# ESP32-S31 register map
Vendor: ESPRESSIF SYSTEMS (SHANGHAI) CO., LTD.; Series: ESP32 S-Series; File version: 1
CPU: RV32IMAFC r0p0, little endian, no MPU, FPU, 0 interrupt priority bits
Address unit: 32 bits
Registers are 32-bit, read-write, reset 0x0 unless marked. A register's access mark holds for its fields unless they carry their own. Offsets are from the block's base; [hi:lo] are bit positions; {n}, {i} and the like mark numbered series.

## LP_SYS — LP System Registers
Base 0x20700000
0x00 VER_DATE reset 0x20250923
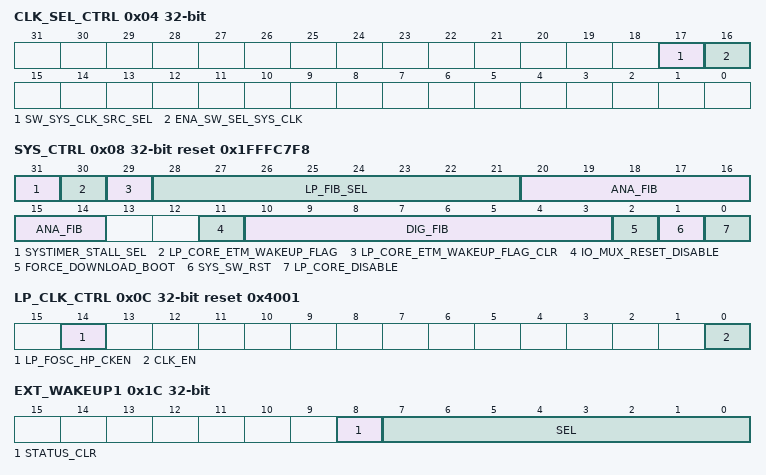
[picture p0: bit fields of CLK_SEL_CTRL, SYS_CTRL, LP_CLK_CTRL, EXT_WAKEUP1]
0x04 CLK_SEL_CTRL
  [17] SW_SYS_CLK_SRC_SEL, [16] ENA_SW_SEL_SYS_CLK
0x08 SYS_CTRL access per field reset 0x1FFFC7F8
  [31] SYSTIMER_STALL_SEL rw, [30] LP_CORE_ETM_WAKEUP_FLAG rw, [29] LP_CORE_ETM_WAKEUP_FLAG_CLR wo, [28:21] LP_FIB_SEL rw, [20:14] ANA_FIB ro, [11] IO_MUX_RESET_DISABLE rw, [10:3] DIG_FIB rw, [2] FORCE_DOWNLOAD_BOOT rw, [1] SYS_SW_RST wo, [0] LP_CORE_DISABLE rw
0x0C LP_CLK_CTRL reset 0x4001
  [14] LP_FOSC_HP_CKEN, [0] CLK_EN
0x18 LP_CORE_BOOT_ADDR reset 0x2E000000
  [31:0] LP_CPU_BOOT_ADDR
0x1C EXT_WAKEUP1 access per field
  [8] STATUS_CLR wo, [7:0] SEL rw
0x20 EXT_WAKEUP1_STATUS ro
  [7:0] EXT_WAKEUP1_STATUS
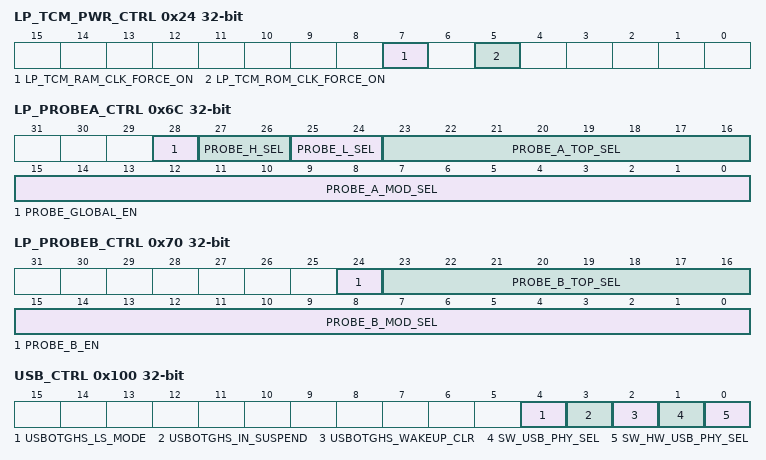
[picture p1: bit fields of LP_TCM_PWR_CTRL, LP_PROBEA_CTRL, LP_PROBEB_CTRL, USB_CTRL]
0x24 LP_TCM_PWR_CTRL
  [7] LP_TCM_RAM_CLK_FORCE_ON, [5] LP_TCM_ROM_CLK_FORCE_ON
0x28 BOOT_ADDR_HP_LP_REG
  [31:0] BOOT_ADDR_HP_LP
{0x2C+4i} LP_STORE{i} (i=0..15)
  [31:0] LP_SCRATCH0
0x6C LP_PROBEA_CTRL
  [28] PROBE_GLOBAL_EN, [27:26] PROBE_H_SEL, [25:24] PROBE_L_SEL, [23:16] PROBE_A_TOP_SEL, [15:0] PROBE_A_MOD_SEL
0x70 LP_PROBEB_CTRL
  [24] PROBE_B_EN, [23:16] PROBE_B_TOP_SEL, [15:0] PROBE_B_MOD_SEL
0x74 LP_PROBE_OUT ro
  [31:0] PROBE_TOP_OUT
0x9C F2S_APB_BRG_CNTL
  [0] F2S_APB_POSTW_EN
0x100 USB_CTRL access per field
  [4] USBOTGHS_LS_MODE rw, [3] USBOTGHS_IN_SUSPEND rw, [2] USBOTGHS_WAKEUP_CLR wo, [1] SW_USB_PHY_SEL rw, [0] SW_HW_USB_PHY_SEL rw
0x10C ANA_XPD_PAD_GROUP reset 0xFF
  [7:0] ANA_REG_XPD_PAD_GROUP
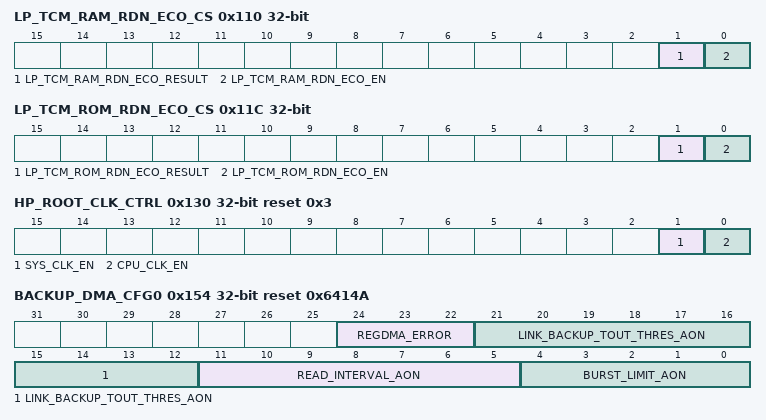
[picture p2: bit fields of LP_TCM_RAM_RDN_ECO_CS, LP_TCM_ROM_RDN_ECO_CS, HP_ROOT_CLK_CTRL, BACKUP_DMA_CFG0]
0x110 LP_TCM_RAM_RDN_ECO_CS access per field
  [1] LP_TCM_RAM_RDN_ECO_RESULT ro, [0] LP_TCM_RAM_RDN_ECO_EN rw
0x114 LP_TCM_RAM_RDN_ECO_LOW
0x118 LP_TCM_RAM_RDN_ECO_HIGH reset 0xFFFFFFFF
0x11C LP_TCM_ROM_RDN_ECO_CS access per field
  [1] LP_TCM_ROM_RDN_ECO_RESULT ro, [0] LP_TCM_ROM_RDN_ECO_EN rw
0x120 LP_TCM_ROM_RDN_ECO_LOW
0x124 LP_TCM_ROM_RDN_ECO_HIGH reset 0xFFFFFFFF
0x130 HP_ROOT_CLK_CTRL reset 0x3
  [1] SYS_CLK_EN, [0] CPU_CLK_EN
0x138 LP_PMU_RDN_ECO_LOW
  [31:0] PMU_RDN_ECO_LOW
0x13C LP_PMU_RDN_ECO_HIGH reset 0xFFFFFFFF
  [31:0] PMU_RDN_ECO_HIGH
0x154 BACKUP_DMA_CFG0 access per field reset 0x6414A
  [24:22] REGDMA_ERROR ro, [21:12] LINK_BACKUP_TOUT_THRES_AON rw, [11:5] READ_INTERVAL_AON rw, [4:0] BURST_LIMIT_AON rw
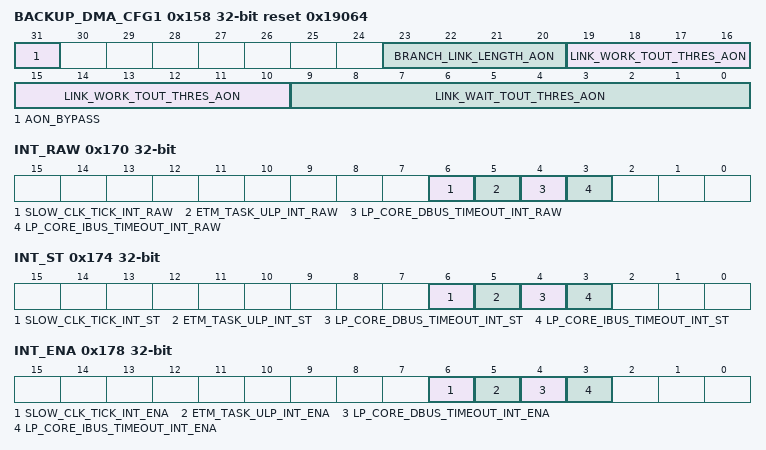
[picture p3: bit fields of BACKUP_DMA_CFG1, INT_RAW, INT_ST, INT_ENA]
0x158 BACKUP_DMA_CFG1 reset 0x19064
  [31] AON_BYPASS, [23:20] BRANCH_LINK_LENGTH_AON, [19:10] LINK_WORK_TOUT_THRES_AON, [9:0] LINK_WAIT_TOUT_THRES_AON
0x15C BACKUP_DMA_CFG2
  [31:0] LINK_ADDR_AON
0x164 BOOT_ADDR_HP_CORE1
0x170 INT_RAW
  [6] SLOW_CLK_TICK_INT_RAW, [5] ETM_TASK_ULP_INT_RAW, [4] LP_CORE_DBUS_TIMEOUT_INT_RAW, [3] LP_CORE_IBUS_TIMEOUT_INT_RAW
0x174 INT_ST ro
  [6] SLOW_CLK_TICK_INT_ST, [5] ETM_TASK_ULP_INT_ST, [4] LP_CORE_DBUS_TIMEOUT_INT_ST, [3] LP_CORE_IBUS_TIMEOUT_INT_ST
0x178 INT_ENA
  [6] SLOW_CLK_TICK_INT_ENA, [5] ETM_TASK_ULP_INT_ENA, [4] LP_CORE_DBUS_TIMEOUT_INT_ENA, [3] LP_CORE_IBUS_TIMEOUT_INT_ENA
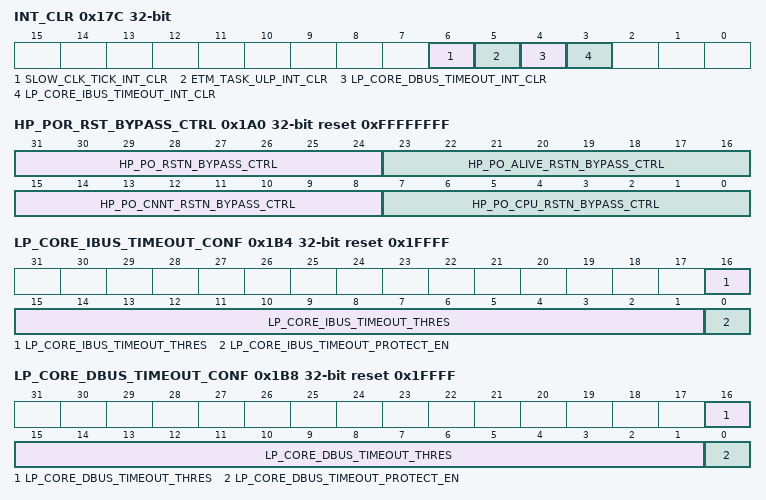
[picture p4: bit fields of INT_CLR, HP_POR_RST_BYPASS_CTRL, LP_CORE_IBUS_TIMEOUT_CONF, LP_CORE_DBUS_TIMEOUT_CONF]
0x17C INT_CLR wo
  [6] SLOW_CLK_TICK_INT_CLR, [5] ETM_TASK_ULP_INT_CLR, [4] LP_CORE_DBUS_TIMEOUT_INT_CLR, [3] LP_CORE_IBUS_TIMEOUT_INT_CLR
0x180 SPRF_MEM_AUX_CTRL reset 0x2070
0x190 LP_CPU_DBG_PC ro
0x194 LP_CPU_EXC_PC ro
0x1A0 HP_POR_RST_BYPASS_CTRL reset 0xFFFFFFFF
  [31:24] HP_PO_RSTN_BYPASS_CTRL, [23:16] HP_PO_ALIVE_RSTN_BYPASS_CTRL, [15:8] HP_PO_CNNT_RSTN_BYPASS_CTRL, [7:0] HP_PO_CPU_RSTN_BYPASS_CTRL
0x1A4 RNG_DATA ro
  [31:0] RND_DATA
0x1B4 LP_CORE_IBUS_TIMEOUT_CONF reset 0x1FFFF
  [16:1] LP_CORE_IBUS_TIMEOUT_THRES, [0] LP_CORE_IBUS_TIMEOUT_PROTECT_EN
0x1B8 LP_CORE_DBUS_TIMEOUT_CONF reset 0x1FFFF
  [16:1] LP_CORE_DBUS_TIMEOUT_THRES, [0] LP_CORE_DBUS_TIMEOUT_PROTECT_EN
0x1BC LP_CORE_ERR_RESP_DIS
  [2:0] LP_CORE_ERR_RESP_DIS
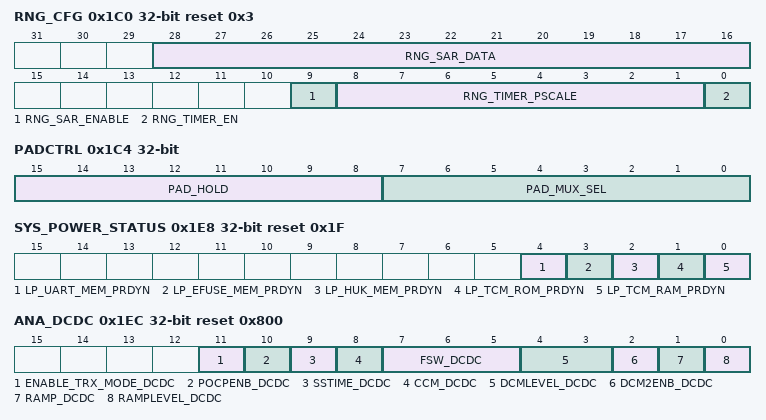
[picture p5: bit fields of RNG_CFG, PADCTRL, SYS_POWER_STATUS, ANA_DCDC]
0x1C0 RNG_CFG access per field reset 0x3
  [28:16] RNG_SAR_DATA ro, [9] RNG_SAR_ENABLE rw, [8:1] RNG_TIMER_PSCALE rw, [0] RNG_TIMER_EN rw
0x1C4 PADCTRL
  [15:8] PAD_HOLD, [7:0] PAD_MUX_SEL
0x1E8 SYS_POWER_STATUS ro reset 0x1F
  [4] LP_UART_MEM_PRDYN, [3] LP_EFUSE_MEM_PRDYN, [2] LP_HUK_MEM_PRDYN, [1] LP_TCM_ROM_PRDYN, [0] LP_TCM_RAM_PRDYN
0x1EC ANA_DCDC reset 0x800
  [11] ENABLE_TRX_MODE_DCDC, [10] POCPENB_DCDC, [9] SSTIME_DCDC, [8] CCM_DCDC, [7:5] FSW_DCDC, [4:3] DCMLEVEL_DCDC, [2] DCM2ENB_DCDC, [1] RAMP_DCDC, [0] RAMPLEVEL_DCDC
0x1F0 POR_CUR_ST ro
  [8:0] POR_CUR_ST
0x1F8 SPRAM_MEM_AUX_CTRL reset 0x2070
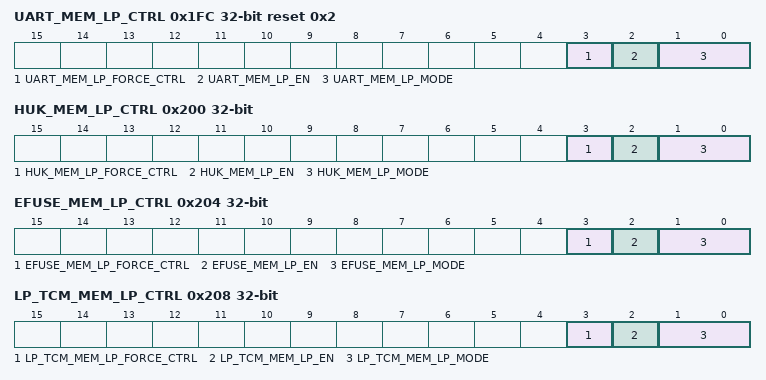
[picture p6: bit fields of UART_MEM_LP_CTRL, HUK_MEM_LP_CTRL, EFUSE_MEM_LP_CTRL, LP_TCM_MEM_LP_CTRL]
0x1FC UART_MEM_LP_CTRL reset 0x2
  [3] UART_MEM_LP_FORCE_CTRL, [2] UART_MEM_LP_EN, [1:0] UART_MEM_LP_MODE
0x200 HUK_MEM_LP_CTRL
  [3] HUK_MEM_LP_FORCE_CTRL, [2] HUK_MEM_LP_EN, [1:0] HUK_MEM_LP_MODE
0x204 EFUSE_MEM_LP_CTRL
  [3] EFUSE_MEM_LP_FORCE_CTRL, [2] EFUSE_MEM_LP_EN, [1:0] EFUSE_MEM_LP_MODE
0x208 LP_TCM_MEM_LP_CTRL
  [3] LP_TCM_MEM_LP_FORCE_CTRL, [2] LP_TCM_MEM_LP_EN, [1:0] LP_TCM_MEM_LP_MODE
0x218 MODEM_MEM_CLK_SEL
  [0] MODEM_MEM_CLK_SEL
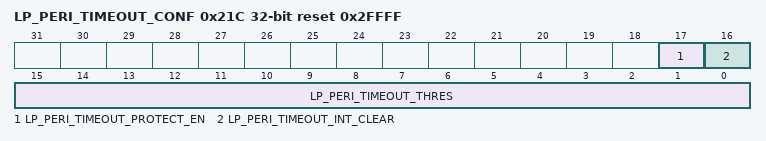
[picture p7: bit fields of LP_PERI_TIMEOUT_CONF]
0x21C LP_PERI_TIMEOUT_CONF access per field reset 0x2FFFF
  [17] LP_PERI_TIMEOUT_PROTECT_EN rw, [16] LP_PERI_TIMEOUT_INT_CLEAR wo, [15:0] LP_PERI_TIMEOUT_THRES rw
0x220 LP_PERI_TIMEOUT_ADDR ro
0x224 LP_PERI_TIMEOUT_UID ro
  [7:0] LP_PERI_TIMEOUT_UID
0x228 RTC_EN_AMUX
  [17:0] RTC_EN_AMUX
0x22C RTC_EN_DMUX
  [1:0] RTC_EN_DMUX
0x230 DIGMUX_PAD_DSEL
  [5:0] DIGMUX_PAD_DSEL
0x234 JTAG_TDIO_MUX_SEL
  [1:0] JTAG_TDIO_MUX_SEL
0x238 LP_CORE_DMACTIVE_LPCORE ro
  [0] LP_CORE_DMACTIVE_LPCORE
0x23C TOUCH_PAD_RTC_EN_AMUX
  [13:0] TOUCH_PAD_RTC_EN_AMUX
0x270 HP_GPIO_O_HOLD_CTRL1
  [22:0] HP_GPIO_0_HOLD_CTRL1
0x274 HP_GPIO_O_HOLD_CTRL0
  [31:0] HP_GPIO_0_HOLD_CTRL0
